# platform_designer_hps_system_hps_0_hps register map
Vendor: default_vendor.com; File version: 0.0
Registers are 32-bit, read-write, reset 0x0 unless marked. A register's access mark holds for its fields unless they carry their own. Offsets are from the block's base; [hi:lo] are bit positions; <NAME> marks a mode.

## sdmmc — Registers in the SD/MMC module
Base 0xFF704000
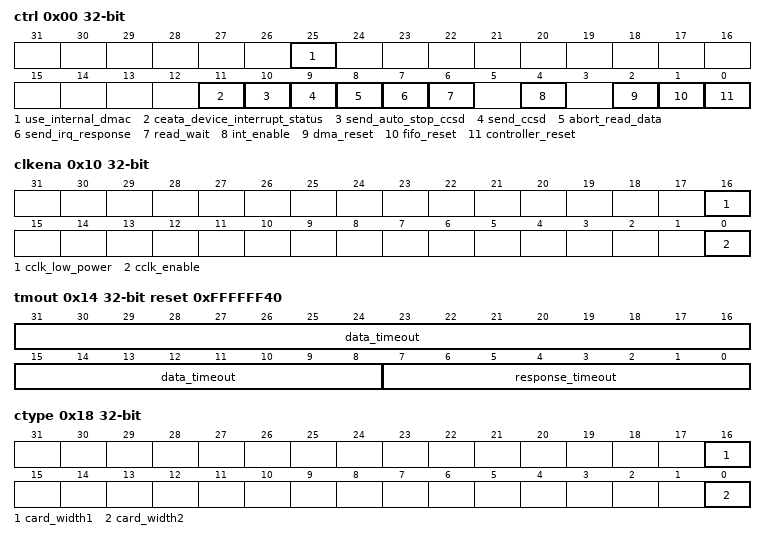
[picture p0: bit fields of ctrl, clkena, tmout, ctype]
0x00 ctrl — Sets various operating condiitions.
  [25] use_internal_dmac — Enable and Disable Internal DMA transfers.
    0=disabled; 1=enabled
  [11] ceata_device_interrupt_status — Software should appropriately write to this bit after power-on reset or any other reset to CE-ATA device. After reset, usually CE-ATA device interrupt is disabled (nIEN = 1). If the host enables CE-ATA device interrupt, then software should set this bit.
    0=disabled; 1=enabled
  [10] send_auto_stop_ccsd — Always set send_auto_stop_ccsd and send_ccsd bits together; send_auto_stop_ccsd should not be set independent of send_ccsd. When set, SD/MMC automatically sends internally generated STOP command (CMD12) to CE-ATA device. After sending internally-generated STOP command, Auto Command Done (ACD) bit in RINTSTS is set and generates interrupt to host if Auto CommandDone interrupt is not masked. After sending the CCSD, SD/MMC automatically clears send_auto_stop_ccsd bit.
    0=deassert; 1=assert
  [9] send_ccsd — When set, SD/MMC sends CCSD to CE-ATA device. Software sets this bit only if current command is expecting CCS (that is, RW_BLK) and interrupts are enabled in CE-ATA device. Once the CCSD pattern is sent to device, SD/MMC automatically clears send_ccsd bit. It also sets Command Done (CD) bit in RINTSTS register and generates interrupt to host if Command Done interrupt is not masked. NOTE: Once send_ccsd bit is set, it takes two card clock cycles to drive the CCSD on the CMD line. Due to this, during the boundary conditions it may happen that CCSD is sent to the CE-ATA device, even if the device signalled CCS.
    0=deassert; 1=assert
  [8] abort_read_data — After suspend command is issued during read-transfer, software polls card to find when suspend happened. Once suspend occurs software sets bit to reset data state-machine, which is waiting for next block of data. Bit automatically clears once data statemachine resets to idle. Used in SDIO card suspend sequence.
    0=nochange; 1=activate
  [7] send_irq_response — Bit automatically clears once response is sent. To wait for MMC card interrupts, host issues CMD40, and SD/MMC waits for interrupt response from MMC card(s). In meantime, if host wants SD/MMC to exit waiting for interrupt state, it can set this bit, at which time SD/MMC command state-machine sends CMD40 response on bus and returns to idle state.
    0=nochange; 1=activate
  [6] read_wait — For sending read-wait to SDIO cards.
    0=deassert; 1=assert
  [4] int_enable — This bit enables and disable interrupts if one or more unmasked interrupts are set.
    0=disabled; 1=enabled
  [2] dma_reset — This bit resets the DMA interface control logic
    0=nochange; 1=activate
  [1] fifo_reset — This bit resets the FIFO. This bit is auto-cleared after completion of reset operation.
    0=nochange; 1=activate
  [0] controller_reset — This bit resets the controller. This bit is auto-cleared after two l4_mp_clk and two sdmmc_clk clock cycles. This resets: - BIU/CIU interface - CIU and state machines - abort_read_data, send_irq_response, and read_wait bits of control register -start_cmd bit of command register Does not affect any registers, DMA interface, FIFO or host interrupts.
    0=nochange; 1=activate
0x04 pwren — Power on/off switch for card; once power is turned on, firmware should wait for regulator/switch ramp-up time before trying to initialize card.
  [0] power_enable — Power on/off switch for one card; for example, bit[0] controls the card. Once power is turned on, firmware should wait for regulator/switch ramp-up time before trying to initialize card.
    0=off; 1=on
0x08 clkdiv — Divides Clock sdmmc_clk.
  [7:0] clk_divider0 — Clock divider-0 value. Clock division is 2*n. For example, value of 0 means divide by 2*0 = 0 (no division, bypass), value of 1 means divide by 2*1 = 2, value of ff means divide by 2*255 = 510, and so on.
0x0C clksrc — Selects among available clock dividers. The sdmmc_cclk_out is always from clock divider 0.
  [1:0] clk_source — Selects among available clock dividers. The SD/MMC module is configured with just one clock divider so this register should always be set to choose clkdiv0.
    0=clkdiv0
0x10 clkena — Controls external SD/MMC Clock Enable.
  [16] cclk_low_power — In low-power mode, stop sdmmc_cclk_out when card in IDLE (should be normally set to only MMC and SD memory cards; for SDIO cards, if interrupts must be detected, clock should not be stopped).
    0=disabled; 1=enabled
  [0] cclk_enable — Enables sdmmc_cclk_out.
    0=disabled; 1=enabled
0x14 tmout reset 0xFFFFFF40 — Sets timeout values
  [31:8] data_timeout — Value for card Data Read Timeout; same value also used for Data Starvation by Host timeout. Value is in number of card output clocks sdmmc_cclk_out of selected card.
  [7:0] response_timeout — Response timeout value. Value is in number of card output clocks sdmmc_cclk_out.
0x18 ctype — Describes card formats.
  [16] card_width1 — Indicates if card is 8 bit or othersize. If not 8-bit, card_width2 specifies the width.
    0=non8bit; 1=mode8bit
  [0] card_width2 — Ignored if card_width1 is MODE8BIT.
    0=mode1bit; 1=mode4bit
0x1C blksiz reset 0x200 — The Block Size.
  [15:0] block_size — The size of a block in bytes.
0x20 bytcnt reset 0x200 — The number of bytes to be transferred.
  [31:0] byte_count — This value should be an integer multiple of the Block Size for block transfers. For undefined number of byte transfers, byte count should be set to 0. When byte count is set to 0, it is responsibility of host to explicitly send stop/abort command to terminate data transfer. Note: In SDIO mode, if a single transfer is greater than 4 bytes and non-DWORD-aligned, the transfer should be broken where only the last transfer is non-DWORD-aligned and less than 4 bytes. For example, if a transfer of 129 bytes must occur, then the driver should start at least two transfers; one with 128 bytes and the other with 1 byte.
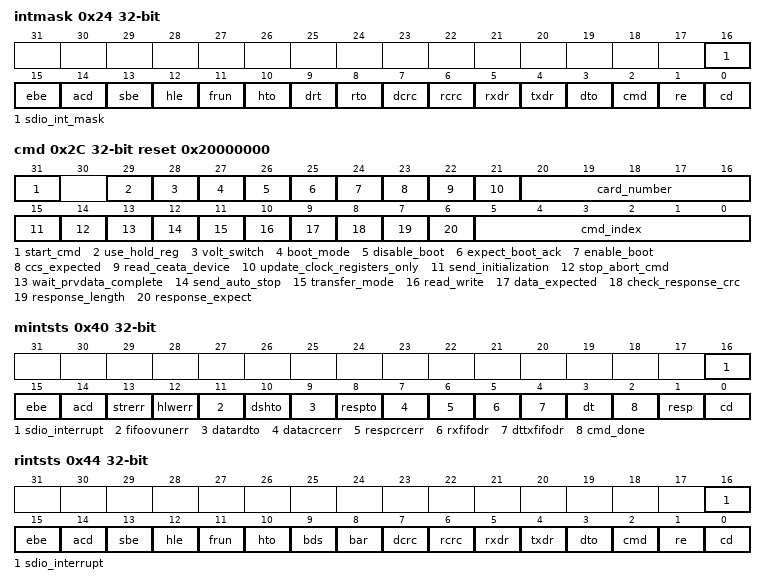
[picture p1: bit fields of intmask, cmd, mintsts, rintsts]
0x24 intmask — Allows Masking of Various Interrupts
  [16] sdio_int_mask — In current application, MMC-Ver3.3 only Bit 16 of this field is used. Bits 17 to 31 are unused and return 0
    0=disabled; 1=enabled
  [15] ebe — Bits used to mask unwanted interrupts. Value of 0 masks interrupts, value of 1 enables interrupt.
    0=mask; 1=nomask
  [14] acd — Bits used to mask unwanted interrupts. Value of 0 masks interrupts, value of 1 enables interrupt.
    0=mask; 1=nomask
  [13] sbe — Bits used to mask unwanted interrupts. Value of 0 masks interrupts, value of 1 enables interrupt.
    0=mask; 1=nomask
  [12] hle — Bits used to mask unwanted interrupts. Value of 0 masks interrupts, value of 1 enables interrupt.
    0=mask; 1=nomask
  [11] frun — Bits used to mask unwanted interrupts. Value of 0 masks interrupts, value of 1 enables interrupt.
    0=mask; 1=nomask
  [10] hto — Bits used to mask unwanted interrupts. Value of 0 masks interrupts, value of 1 enables interrupt.
    0=mask; 1=nomask
  [9] drt — Bits used to mask unwanted interrupts. Value of 0 masks interrupts, value of 1 enables interrupt.
    0=mask; 1=nomask
  [8] rto — Bits used to mask unwanted interrupts. Value of 0 masks interrupts, value of 1 enables interrupt.
    0=mask; 1=nomask
  [7] dcrc — Bits used to mask unwanted interrupts. Value of 0 masks interrupts, value of 1 enables interrupt.
    0=mask; 1=nomask
  [6] rcrc — Bits used to mask unwanted interrupts. Value of 0 masks interrupts, value of 1 enables interrupt.
    0=mask; 1=nomask
  [5] rxdr — Bits used to mask unwanted interrupts. Value of 0 masks interrupts, value of 1 enables interrupt.
    0=mask; 1=nomask
  [4] txdr — Bits used to mask unwanted interrupts. Value of 0 masks interrupts, value of 1 enables interrupt.
    0=mask; 1=nomask
  [3] dto — Bits used to mask unwanted interrupts. Value of 0 masks interrupts, value of 1 enables interrupt.
    0=mask; 1=nomask
  [2] cmd — Bits used to mask unwanted interrupts. Value of 0 masks interrupts, value of 1 enables interrupt.
    0=mask; 1=nomask
  [1] re — Bits used to mask unwanted interrupts. Value of 0 masks interrupts, value of 1 enables interrupt.
    0=mask; 1=nomask
  [0] cd — Bits used to mask unwanted interrupts. Value of 0 masks interrupts, value of 1 enables interrupt.
    0=mask; 1=nomask
0x28 cmdarg — See Field Description.
  [31:0] cmd_arg — Values indicates command argument to be passed to card.
0x2C cmd reset 0x20000000 — This register issues various commands.
  [31] start_cmd — Once command is taken by CIU, bit is cleared. If Start Cmd issued host should not attempt to write to any command registers. If write is attempted, hardware lock error is set in raw interrupt register. Once command is sent and response is received from SD_MMC_CEATA cards, Command Done bit is set in raw interrupt register.
    0=nostart; 1=start
  [29] use_hold_reg — Set to one for SDR12 and SDR25 (with non-zero phase-shifted cclk_in_drv); zero phase shift is not allowed in these modes. -Set to 1'b0 for SDR50, SDR104, and DDR50 (with zero phase-shifted cclk_in_drv). -Set to 1'b1 for SDR50, SDR104, and DDR50 (with non-zero phase-shifted cclk_in_drv).
    0=bypass; 1=nobypass
  [28] volt_switch — Voltage switch bit. When set must be set for CMD11 only.
    0=novoltsw; 1=voltsw
  [27] boot_mode — Type of Boot Mode.
    0=mandatory; 1=alternate
  [26] disable_boot — When software sets this bit along with start_cmd, CIU terminates the boot operation. Do NOT set disable_boot and enable_boot together.
    0=notermboot; 1=termboot
  [25] expect_boot_ack — When Software sets this bit along with enable_boot, CIU expects a boot acknowledge start pattern of 0-1-0 from the selected card.
    0=nobootack; 1=bootack
  [24] enable_boot — This bit should be set only for mandatory boot mode. When Software sets this bit along with start_cmd, CIU starts the boot sequence for the corresponding card by asserting the CMD line low. Do NOT set disable_boot and enable_boot together
    0=disabled; 1=enabled
  [23] ccs_expected — If the command expects Command Completion Signal (CCS) from the CE-ATA device, the software should set this control bit. SD/MMC sets Data Transfer Over (DTO) bit in RINTSTS register and generates interrupt to host if Data Transfer Over interrupt is not masked.
    0=disabled; 1=enabled
  [22] read_ceata_device — Software should set this bit to indicate that CE-ATA device is being accessed for read transfer. This bit is used to disable read data timeout indication while performing CE-ATA read transfers. Maximum value of I/O transmission delay can be no less than 10 seconds. SD/MMC should not indicate read data timeout while waiting for data from CE-ATA device.
    0=nord; 1=rd
  [21] update_clock_registers_only — Following register values transferred into card clock domain: CLKDIV, CLRSRC, CLKENA. Changes card clocks (change frequency, truncate off or on, and set low-frequency mode); provided in order to change clock frequency or stop clock without having to send command to cards. During normal command sequence, when update_clock_registers_only = 0, following control registers are transferred from BIU to CIU: CMD, CMDARG, TMOUT, CTYPE, BLKSIZ, BYTCNT. CIU uses new register values for new command sequence to card(s). When bit is set, there are no Command Done interrupts because no command is sent to SD_MMC_CEATA cards.
    0=normcmd; 1=updatclkreg
  [20:16] card_number — Card number in use must always be 0.
  [15] send_initialization — After power on, 80 clocks must be sent to the card for initialization before sending any commands to card. Bit should be set while sending first command to card so that controller will initialize clocks before sending command to card. This bit should not be set for either of the boot modes (alternate or mandatory).
    0=noinit; 1=init
  [14] stop_abort_cmd — When open-ended or predefined data transfer is in progress, and host issues stop or abort command to stop data transfer, bit should be set so that command/data state-machines of CIU can return correctly to idle state. This is also applicable for Boot mode transfers. To Abort boot mode, this bit should be set along with CMD[26] = disable_boot. Note: If abort is sent to function-number currently selected or not in data-transfer mode, then bit should be set to 0.
    0=nostopabrt; 1=stopabrt
  [13] wait_prvdata_complete — Determines when command is sent. The send command at once option is typically used to query status of card during data transfer or to stop current data transfer.
    0=nowait; 1=wait
  [12] send_auto_stop — When set, SD/MMC sends stop command to SD_MMC_CEATA cards at end of data transfer. Determine the following: *-when send_auto_stop bit should be set, since some data transfers do not need explicit stop commands. *-open-ended transfers that software should explicitly send to stop command. Additionally, when resume is sent to resume- suspended memory access of SD-Combo card, bit should be set correctly if suspended data transfer needs send_auto_stop. Don't care if no data expected from card.
    0=nosend; 1=send
  [11] transfer_mode — Block transfer command. Don't care if no data expected
    0=blk; 1=str
  [10] read_write — Read/Write from card. Don't care if no data transfer expected.
    0=rd; 1=wr
  [9] data_expected — Set decision on data transfer expecetd or not.
    0=nodatxferexp; 1=dataxferexp
  [8] check_response_crc — Some of command responses do not return valid CRC bits. Software should disable CRC checks for those commands in order to disable CRC checking by controller.
    0=nochk; 1=chk
  [7] response_length — Provides long and short response
    0=short; 1=long
  [6] response_expect — Response expected from card.
    0=resp; 1=noresp
  [5:0] cmd_index — Tracks the command index number. Values from 0-31.
0x30 resp0 ro — Preserves previous command.
  [31:0] response0 — Bit[31:0] of response.
0x34 resp1 ro
  [31:0] response1 — Register represents bit[63:32] of long response. When CIU sends auto-stop command, then response is saved in register. Response for previous command sent by host is still preserved in Response 0 register. Additional auto-stop issued only for data transfer commands, and response type is always short for them.
0x38 resp2 ro
  [31:0] response2 — Bit[95:64] of long response
0x3C resp3 ro
  [31:0] response3 — Bit[127:96] of long response
0x40 mintsts ro — Describes state of Masked Interrupt Register.
  [16] sdio_interrupt — Interrupt from SDIO card: one bit for each card. Bit[16] is for Card[0]. SDIO interrupt for card enabled only if corresponding sdio_int_mask bit is set in Interrupt mask register (mask bit 1 enables interrupt; 0 masks interrupt). In MMC-Ver3.3-only mode, bits always 0.
    1=active; 0=inactive
  [15] ebe — Interrupt enabled only if corresponding bit in interrupt mask register is set.
    0=mask; 1=nomask
  [14] acd — Interrupt enabled only if corresponding bit in interrupt mask register is set.
    0=mask; 1=nomask
  [13] strerr — Interrupt enabled only if corresponding bit in interrupt mask register is set.
    0=mask; 1=nomask
  [12] hlwerr — Interrupt enabled only if corresponding bit in interrupt mask register is set.
    0=mask; 1=nomask
  [11] fifoovunerr — Interrupt enabled only if corresponding bit in interrupt mask register is set.
    0=mask; 1=nomask
  [10] dshto — Interrupt enabled only if corresponding bit in interrupt mask register is set.
    0=mask; 1=nomask
  [9] datardto — Interrupt enabled only if corresponding bit in interrupt mask register is set.
    0=mask; 1=nomask
  [8] respto — Interrupt enabled only if corresponding bit in interrupt mask register is set.
    0=mask; 1=nomask
  [7] datacrcerr — Interrupt enabled only if corresponding bit in interrupt mask register is set.
    0=mask; 1=nomask
  [6] respcrcerr — Interrupt enabled only if corresponding bit in interrupt mask register is set.
    0=mask; 1=nomask
  [5] rxfifodr — Interrupt enabled only if corresponding bit in interrupt mask register is set.
    0=mask; 1=nomask
  [4] dttxfifodr — Interrupt enabled only if corresponding bit in interrupt mask register is set.
    0=mask; 1=nomask
  [3] dt — Interrupt enabled only if corresponding bit in interrupt mask register is set.
    0=mask; 1=nomask
  [2] cmd_done — Interrupt enabled only if corresponding bit in interrupt mask register is set.
    0=mask; 1=nomask
  [1] resp — Interrupt enabled only if corresponding bit in interrupt mask register is set.
    0=mask; 1=nomask
  [0] cd — Interrupt enabled only if corresponding bit in interrupt mask register is set.
    0=mask; 1=nomask
0x44 rintsts — Interrupt Status Before Masking.
  [16] sdio_interrupt write-1-clears — Interrupt from SDIO card.
    1=active; 0=inactive
  [15] ebe write-1-clears — Writes to bits clear status bit. Value of 1 clears status bit, and value of 0 leaves bit intact. Bits are logged regardless of interrupt mask status.
    0=inactive; 1=active
  [14] acd write-1-clears — Writes to bits clear status bit. Value of 1 clears status bit, and value of 0 leaves bit intact. Bits are logged regardless of interrupt mask status.
    0=inactive; 1=active
  [13] sbe write-1-clears — Writes to bits clear status bit. Value of 1 clears status bit, and value of 0 leaves bit intact. Bits are logged regardless of interrupt mask status.
    0=inactive; 1=active
  [12] hle write-1-clears — Writes to bits clear status bit. Value of 1 clears status bit, and value of 0 leaves bit intact. Bits are logged regardless of interrupt mask status.
    0=inactive; 1=active
  [11] frun write-1-clears — Writes to bits clear status bit. Value of 1 clears status bit, and value of 0 leaves bit intact. Bits are logged regardless of interrupt mask status.
    0=inactive; 1=active
  [10] hto write-1-clears — Writes to bits clear status bit. Value of 1 clears status bit, and value of 0 leaves bit intact. Bits are logged regardless of interrupt mask status.
    0=inactive; 1=active
  [9] bds write-1-clears — Writes to bits clear status bit. Value of 1 clears status bit, and value of 0 leaves bit intact. Bits are logged regardless of interrupt mask status.
    0=inactive; 1=active
  [8] bar write-1-clears — Writes to bits clear status bit. Value of 1 clears status bit, and value of 0 leaves bit intact. Bits are logged regardless of interrupt mask status.
    0=inactive; 1=active
  [7] dcrc write-1-clears — Writes to bits clear status bit. Value of 1 clears status bit, and value of 0 leaves bit intact. Bits are logged regardless of interrupt mask status.
    0=inactive; 1=active
  [6] rcrc write-1-clears — Writes to bits clear status bit. Value of 1 clears status bit, and value of 0 leaves bit intact. Bits are logged regardless of interrupt mask status.
    0=inactive; 1=active
  [5] rxdr write-1-clears — Writes to bits clear status bit. Value of 1 clears status bit, and value of 0 leaves bit intact. Bits are logged regardless of interrupt mask status.
    0=inactive; 1=active
  [4] txdr write-1-clears — Writes to bits clear status bit. Value of 1 clears status bit, and value of 0 leaves bit intact. Bits are logged regardless of interrupt mask status.
    0=inactive; 1=active
  [3] dto write-1-clears — Writes to bits clear status bit. Value of 1 clears status bit, and value of 0 leaves bit intact. Bits are logged regardless of interrupt mask status.
    0=inactive; 1=active
  [2] cmd write-1-clears — Writes to bits clear status bit. Value of 1 clears status bit, and value of 0 leaves bit intact. Bits are logged regardless of interrupt mask status.
    0=inactive; 1=active
  [1] re write-1-clears — Writes to bits clear status bit. Value of 1 clears status bit, and value of 0 leaves bit intact. Bits are logged regardless of interrupt mask status.
    0=inactive; 1=active
  [0] cd write-1-clears — Writes to bits clear status bit. Value of 1 clears status bit, and value of 0 leaves bit intact. Bits are logged regardless of interrupt mask status.
    0=inactive; 1=active
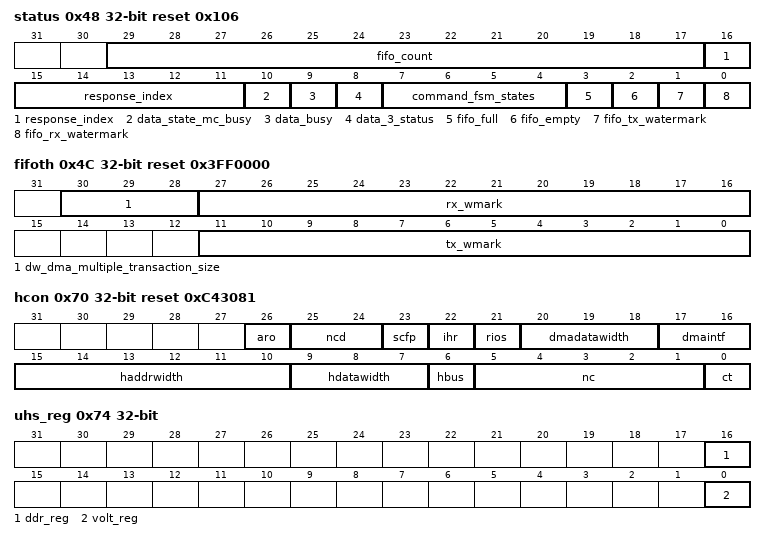
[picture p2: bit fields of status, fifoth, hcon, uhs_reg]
0x48 status ro reset 0x106 — Reports various operting status conditions.
  [29:17] fifo_count — FIFO count - Number of filled locations in FIFO
  [16:11] response_index — Index of previous response, including any auto-stop sent by core
  [10] data_state_mc_busy — Data transmit or receive state-machine is busy.
    1=datastatebsy; 0=datastatenotbsy
  [9] data_busy — Inverted version of raw selected card_data[0]. The default can be cardpresent or not present depend on cdata_in.
    1=cardbusy; 0=cardnotbusy
  [8] data_3_status — Raw selected card_data[3]; checks whether card is present. The default can be cardpresent or not present depend on cdata_in.
    1=cardpresent; 0=cardnotpresent
  [7:4] command_fsm_states — The command FSM state.
    0=idleandothers; 1=sendinitseq; 2=txcmdstart; 3=txcmdtxbit; 4=txcmdindxarg; 5=txcmdcrc7; 6=txcmdend; 7=rxrespstart; 8=rxrespirq; 9=rxresptx; 10=rxrespcmdidx; 11=rxrespdata; 12=rxrespcrc7; 13=rxrespend; 14=cmdpathwait; 15=waitcmdturn
  [3] fifo_full — FIFO is full status.
    0=fifofull; 1=fifonotfull
  [2] fifo_empty — FIFO is empty status.
    1=fifoempty; 0=fifonotempty
  [1] fifo_tx_watermark — FIFO reached Transmit watermark level; not qualified with data transfer.
    1=txwatermark; 0=notxwatermark
  [0] fifo_rx_watermark — FIFO reached Receive watermark level; not qualified with data transfer
    0=rxwatermark; 1=norxwatermark
0x4C fifoth reset 0x3FF0000 — DMA and FIFO Control Fields.
  [30:28] dw_dma_multiple_transaction_size — Burst size of multiple transaction; should be programmed same as DMA controller multiple-transaction-size SRC/DEST_MSIZE. The units for transfers is 32 bits. A single transfer would be signalled based on this value. Value should be sub-multiple of 512. Allowed combinations for MSize and TX_WMark.
    0=txmsize1; 1=txmsize4; 2=txmsizek8; 3=txmsizek16; 5=rxmsizek1; 6=rxmsizek4; 7=rxmsize8
  [27:16] rx_wmark — FIFO threshold watermark level when receiving data to card. When FIFO data count reaches greater than this number, DMA/FIFO request is raised. During end of packet, request is generated regardless of threshold programming in order to complete any remaining data. In non-DMA mode, when receiver FIFO threshold (RXDR) interrupt is enabled, then interrupt is generated instead of DMA request. During end of packet, interrupt is not generated if threshold programming is larger than any remaining data. It is responsibility of host to read remaining bytes on seeing Data Transfer Done interrupt. In DMA mode, at end of packet, even if remaining bytes are less than threshold, DMA request does single transfers to flush out any remaining bytes before Data Transfer Done interrupt is set. 12 bits - 1 bit less than FIFO-count of status register, which is 13 bits. Limitation: RX_WMark <= 1022 Recommended: 511; means greater than (FIFO_DEPTH/2) - 1) NOTE: In DMA mode during CCS time-out, the DMA does not generate the request at the end of packet, even if remaining bytes are less than threshold. In this case, there will be some data left in the FIFO. It is the responsibility of the application to reset the FIFO after the CCS timeout.
  [11:0] tx_wmark — FIFO threshold watermark level when transmitting data to card. When FIFO data count is less than or equal to this number, DMA/FIFO request is raised. If Interrupt is enabled, then interrupt occurs. During end of packet, request or interrupt is generated, regardless of threshold programming. In non-DMA mode, when transmit FIFO threshold (TXDR) interrupt is enabled, then interrupt is generated instead of DMA request. During end of packet, on last interrupt, host is responsible for filling FIFO with only required remaining bytes (not before FIFO is full or after CIU completes data transfers, because FIFO may not be empty). In DMA mode, at end of packet, if last transfer is less than burst size, DMA controller does single cycles until required bytes are transferred. 12 bits - 1 bit less than FIFO-count of status register, which is 13 bits. Limitation: TX_WMark >= 1; Recommended: FIFO_DEPTH/2 = 512; (means less than or equal to 512)
0x50 cdetect ro reset 0x1 — Determines if card is present.
  [0] card_detect_n — Value on sdmmc_cd_i input port.
    1=notdetected; 0=detected
0x54 wrtprt ro reset 0x1 — See Field Description.
  [0] write_protect — Value on sdmmc_wp_i input port.
    1=enabled; 0=disabled
0x5C tcbcnt ro
  [31:0] trans_card_byte_count — Number of bytes transferred by CIU unit to card.
0x60 tbbcnt ro — Tracks number of bytes transferred between Host and FIFO.
  [31:0] trans_fifo_byte_count — Number of bytes transferred between Host/DMA memory and BIU FIFO. In 32-bit AMBA data-bus-width modes, register should be accessed in full to avoid read-coherency problems. Both TCBCNT and TBBCNT share same coherency register.
0x64 debnce reset 0xFFFFFF
  [23:0] debounce_count — Number of host clocks l4_mp_clk used by debounce filter logic; typical debounce time is 5-25 ms.
0x68 usrid reset 0x7967797
  [31:0] usr_id — User identification field; Value is 0x7967797.
0x6C verid ro reset 0x5342240A
  [31:0] ver_id — Synopsys version id. Current value is 32'h5342240a
0x70 hcon ro reset 0xC43081 — Hardware configurations registers. Register can be used to develop configuration-independent software drivers.
  [26] aro — Area optimized
    0=notoptforarea
  [25:24] ncd — Number of clock dividers less one
    0=onediv
  [23] scfp — Clock False Path
    1=set
  [22] ihr — Implement hold register
    1=implemented
  [21] rios — FIFO RAM location
    0=outside
  [20:18] dmadatawidth — Encodes bit width of external DMA controller interface. Doesn't apply to the SD/MMC because it has no external DMA controller interface.
    1=width32bits
  [17:16] dmaintf — DMA interface type
    0=none
  [15:10] haddrwidth — Slave bus address width less one
    12=width13bits
  [9:7] hdatawidth — Slave bus data width
    1=width32bits
  [6] hbus — Slave bus type.
    0=apb
  [5:1] nc — Maximum number of cards less one
    0=numcard
  [0] ct — Supported card types
    1=sdmmc
0x74 uhs_reg — UHS-1 Register
  [16] ddr_reg — Determines the voltage fed to the buffers by an external voltage regulator.
    0=nonddr; 1=ddr
  [0] volt_reg — Determines the voltage fed to the buffers by an external voltage regulator. These bits function as the output of the host controller and are fed to an external voltage regulator. The voltage regulator must switch the voltage of the buffers of a particular card to either 3.3V or 1.8V, depending on the value programmed in the register.
    0=buf33v; 1=buf18v
0x78 rst_n reset 0x1
  [0] card_reset — This bit causes the cards to enter pre-idle state, which requires it to be re-initialized.
    1=assert; 0=deassert
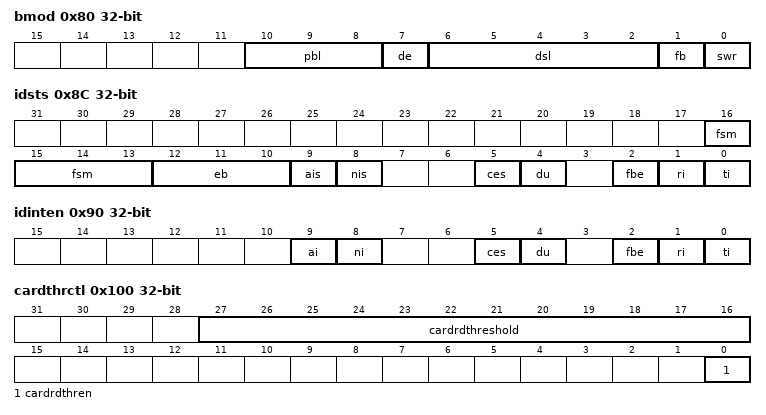
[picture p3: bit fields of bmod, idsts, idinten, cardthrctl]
0x80 bmod — Details different bus operating modes.
  [10:8] pbl ro — These bits indicate the maximum number of beats to be performed in one IDMAC transaction. The IDMAC will always attempt to burst as specified in PBL each time it starts a Burst transfer on the host bus. This value is the mirror of MSIZE of FIFOTH register. In order to change this value, write the required value to FIFOTH register. This is an encode value as follows.
    0=trans1; 1=trans4; 2=trans8; 3=trans16; 4=trans32; 5=trans64; 6=trans128; 7=trans256
  [7] de — Enables and Disables Internal DMA.
    1=enabled; 0=disabled
  [6:2] dsl — Specifies the number of HWord/Word/Dword (depending on 16/32/64-bit bus) to skip between two unchained descriptors.
  [1] fb — Controls whether the AHB Master interface performs fixed burst transfers or not. Will use only SINGLE, INCR4, INCR8 or INCR16 during start of normal burst transfers.
    1=fixedbrst; 0=nofixedbrst
  [0] swr — This bit resets all internal registers of the DMA Controller. It is automatically cleared after 1 clock cycle.
    1=sftreset; 0=nosftreset
0x84 pldmnd wo — See Field Description.
  [31:0] pd — If the OWN bit of a descriptor is not set, the FSM goes to the Suspend state. The host needs to write any value into this register for the IDMAC FSM to resume normal descriptor fetch operation.
0x88 dbaddr — See Field Descriptor
  [31:2] sdl — Contains the base address of the First Descriptor. This is the byte address divided by 4.
0x8C idsts — Sets Internal DMAC Status Fields
  [16:13] fsm ro — DMAC FSM present state.
    0=dmaidle; 1=dmasuspend; 2=descrd; 3=descchk; 4=dmardreqwait; 5=dmawrreqwait; 6=dmard; 7=dmawr; 8=decclose
  [12:10] eb ro — Indicates the type of error that caused a Bus Error. Valid only with Fatal Bus Error bit (IDSTS[2]) set. This field does not generate an interrupt.
    1=hostarbttx; 2=hostarbrx
  [9] ais write-1-clears — Logical OR of the following: IDSTS[2] - Fatal Bus Interrupt IDSTS[4] - DU bit Interrupt IDSTS[5] - Card Error Summary Interrupt Only unmasked bits affect this bit. This is a sticky bit and must be cleared each time a corresponding bit that causes AIS to be set is cleared.
    1=clr; 0=noclr
  [8] nis write-1-clears — Logical OR of the following: IDSTS[0] - Transmit Interrupt IDSTS[1] - Receive Interrupt Only unmasked bits affect this bit. This is a sticky bit and must be cleared each time a corresponding bit that causes NIS to be set is cleared.
    1=clr; 0=noclr
  [5] ces write-1-clears — Indicates the status of the transaction to/from the card; also present in RINTSTS. Indicates the logical OR of the following bits: EBE - End Bit Error RTO - Response Timeout/Boot Ack Timeout RCRC - Response CRC SBE - Start Bit Error DRTO - Data Read Timeout/BDS timeout DCRC - Data CRC for Receive RE - Response Error
    1=clr; 0=noclr
  [4] du write-1-clears — This status bit is set when the descriptor is unavailable due to OWN bit = 0 (DES0[31] =0).
    1=clr; 0=noclr
  [2] fbe write-1-clears — Indicates that a Bus Error occurred (IDSTS[12:10]). When setthe DMA disables all its bus accesses.
    1=clr; 0=noclr
  [1] ri write-1-clears — Indicates the completion of data reception for a descriptor
    1=clr; 0=noclr
  [0] ti write-1-clears — Indicates that data transmission is finished for a descriptor.
    1=clr; 0=noclr
0x90 idinten — Various DMA Interrupt Enable Status
  [all] fields
    1=enabled; 0=disabled
  [9] ai — This bit enables the following bits: IDINTEN[2] - Fatal Bus Error Interrupt IDINTEN[4] - DU Interrupt IDINTEN[5] - Card Error Summary Interrupt
  [8] ni — Enable and Disable Normal Interrupt Summary
  [5] ces — Enable and disable Card Error Interrupt Summary
  [4] du — When set along with Abnormal Interrupt Summary Enable, the DU interrupt is enabled.
  [2] fbe — When set with Abnormal Interrupt Summary Enable, the Fatal Bus Error Interrupt is enabled.
  [1] ri — Enables and Disables Receive Interrupt when Normal Interrupt Summary Enable is set.
  [0] ti — Enables and Disables Transmit Interrupt when Normal Interrupt Summary Enable is set.
0x94 dscaddr ro — See Field Description.
  [31:0] hda — Cleared on reset. Pointer updated by IDMAC during operation. This register points to the start address of the current descriptor read by the IDMAC.
0x98 bufaddr ro — See Field Description.
  [31:0] hba — Cleared on Reset. Pointer updated by IDMAC during operation. This register points to the current Data Buffer Address being accessed by the IDMAC.
0x100 cardthrctl — See Field descriptions
  [27:16] cardrdthreshold — Card Read Threshold size
  [0] cardrdthren — Host Controller initiates Read Transfer only if CardRdThreshold amount of space is available in receive FIFO.
    1=enabled; 0=disabled
0x104 back_end_power_r — See Field Description
  [15:0] back_end_power — Back end power operation.
    1=backend1; 0=backend0
0x200 data reset not defined — Provides read/write access to data FIFO. Addresses 0x200 and above are mapped to the data FIFO. More than one address is mapped to data FIFO so that FIFO can be accessed using bursts.
  [31:0] value — Provides read/write access to data FIFO.
